# MMCSD2_CTL_CFG register map
Vendor: Texas Instruments
Registers are 16-bit, read-only, reset 0x0 unless marked. A register's access mark holds for its fields unless they carry their own. Offsets are as the file gives them; [hi:lo] are bit positions; {n}, {i} and the like mark numbered series.

## MMCSD2_CTL_CFG (part 2 of 3)
0x00 MMCSD12_SDMA_SYS_ADDR_LO rw — This register contains the Lower 16-bit of physical system memory address used for DMA transfers or the second argument for the Auto CMD23 in Host version 3.0 and as 32-bit Block Count in Version 4.10.
  [15:0] SDMA_ADDRESS — 32-bit Block Count (SDMA System Address) Low When the When the (1) SDMA System Address ( This register contains the system memory address for a SDMA transfer in 32-bit addressing mode. When the Host Controller (HC) stops a SDMA transfer, this register shall point to the system address of the next contiguous data position. It can be accessed only if no transaction is executing (after a transaction has stopped). Reading this register during SDMA transfers may return an invalid value. The Host Driver (HD) shall initialize this register before starting a SDMA transaction. After SDMA has stopped, the next system address of the next contiguous data position can be read from this register. The SDMA transfer waits at the every boundary specified by the (2) 32-bit Block Count ( Host Controller Version 4.10 re-defines this register as 32-bit Block Count. In version 4.00, this register may be used as 32-bit block count only for Auto CMD23 to set the argument of the CMD23 while executing Auto CMD23. The Host Controller would decrement the block count of this register every block transfer and data transfer stops when the count reaches zero.
0x02 MMCSD12_SDMA_SYS_ADDR_HI rw — This register contains the Upper 16-bit of physical system memory address used for DMA transfers or the second argument for the Auto CMD23 in Host version 3.0 and as 32-bit Block Count in Version 4.10.
  [15:0] SDMA_ADDRESS — 32-bit Block Count (SDMA System Address) High This register contains the Upper 16-bit of physical system memory address used for DMA transfers or the second argument for the Auto CMD23 in Host version 3.0 and as 32-bit Block Count in Version 4.10.
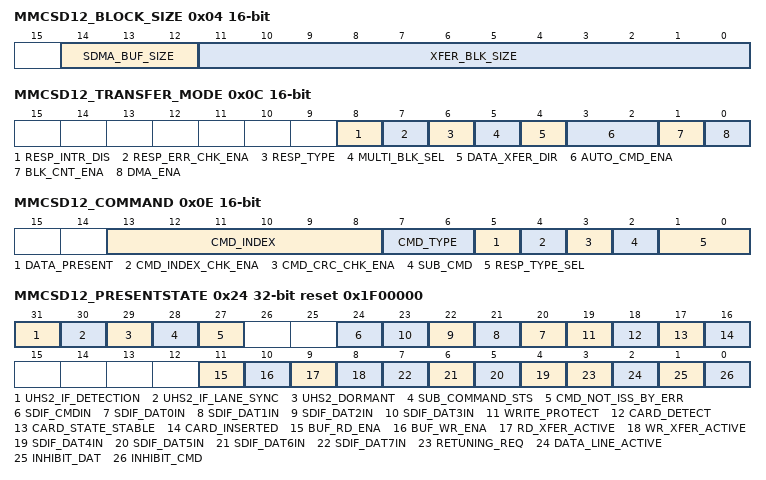
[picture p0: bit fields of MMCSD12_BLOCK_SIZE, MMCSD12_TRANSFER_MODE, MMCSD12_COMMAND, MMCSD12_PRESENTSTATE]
0x04 MMCSD12_BLOCK_SIZE access per field — This register is used to configure the number of bytes in a data block.
  [14:12] SDMA_BUF_SIZE rw — Host SDMA Buffer Size To perform long DMA transfer, System Address register ( These bits shall support when the 0h: 4KB (Detects A11 Carry out) 1h: 8KB (Detects A12 Carry out) 2h: 16KB (Detects A13 Carry out) 3h: 32KB (Detects A14 Carry out) 4h: 64KB (Detects A15 Carry out) 5h: 128KB (Detects A16 Carry out) 6h: 256KB (Detects A17 Carry out) 7h: 512KB (Detects A18 Carry out)
  [11:0] XFER_BLK_SIZE rw — Transfer Block Size This field specifies the block size for block data transfers for CMD17, CMD18, CMD24, CMD25 and CMD53. It can be accessed only if no transaction is executing (after a transaction has stopped). Read operations during transfer return an invalid value and write operations shall be ignored. 0000h: No Data Transfer 0001h: 1 Byte 0002h: 2 Bytes 0003h: 3 Bytes 0004h: 4 Bytes .... 01FFh: 511 Bytes 0200h: 512 Bytes .... 0800h: 2048 Bytes
0x06 MMCSD12_BLOCK_COUNT rw — This register is used to configure the number of data blocks.
  [15:0] XFER_BLK_CNT — 16-bit Block Count Host Controller Version 4.10 extends block count to 32-bit. Selection of either 16-bit Block Count register or 32-bit Block Count register is defined as follows: (1) If the (2) If the Use of 16-bit/32-bit Block Count register is enabled when the The Host Driver shall set this register to a value between 1h and the maximum block count. The Host Controller decrements the block count after each block transfer and stops when the count reaches zero. Setting the block count to 0h results in no data blocks is transferred. This register should be accessed only when no transaction is executing (after transactions are stopped). During data transfer, read operations on this register may return an invalid value and write operations are ignored. 0000h: Stop Count 0001h: 1 Block 0002h: 2 Blocks .... FFFFh: 65535 Blocks
0x08 MMCSD12_ARGUMENT1_LO rw — This register contains Lower bits of SD Command Argument.
  [15:0] CMD_ARG1 — Command Argument 1 Low The SD Command Argument is specified as bit 23-8 of Command-Format.
0x0A MMCSD12_ARGUMENT1_HI rw — This register contains higher bits of SD Command Argument.
  [15:0] CMD_ARG1 — Command Argument 1 High The SD Command Argument is specified as bit 39-24 of Command-Format.
0x0C MMCSD12_TRANSFER_MODE access per field
  [8] RESP_INTR_DIS rw — Response Interrupt Disable Host Controller Version 4.00 supports response error check function to avoid overhead of response error check by Host Driver. Only R1 or R5 can be checked. If Host Driver checks response error, sets this bit to 0h and waits Command Complete Interrupt ( If Host Controller checks response error, sets this bit to 1h and sets the 0h: Response Interrupt is enabled 1h: Response Interrupt is disabled
  [7] RESP_ERR_CHK_ENA rw — Response Error Check Enable Host Controller Version 4.00 supports response error check function to avoid overhead of response error check by Host Driver. Only R1 or R5 can be checked. If Host Driver checks response error, this bit is set to 0h and the If Host Controller checks response error, sets this bit to 1h and sets the Response Interrupt Disable bit to 1h ( The 0h: Response Error Check is disabled 1h: Response Error Check is enabled
  [6] RESP_TYPE rw — Response Type R1/R5 When response error check is enabled ( Error Statuses Checked in R1: Response Flags Checked in R5: 0h: R1 (Memory) 1h: R5 (SDIO)
  [5] MULTI_BLK_SEL rw — Multi/Single Block Select This bit enables multiple block data transfers. 0h: Single Block 1h: Multiple Block
  [4] DATA_XFER_DIR rw — Data Transfer Direction Select This bit defines the direction of data transfers. 0h: Write (Host to Card) 1h: Read (Card to Host)
  [3:2] AUTO_CMD_ENA rw — Auto CMD Enable This field determines use of auto command functions. There are three methods to stop Multiple-block read and write operation by CMD23 or CMD12. In the other operations (for example single read/write operation), this field is set to 0h. (1) Auto CMD12 Enable: Multiple-block read and write commands for memory require CMD12 to stop the operation. When this field is set to 1h, the Host Controller issues CMD12 automatically when last block transfer is completed. Auto CMD12 error is indicated to the When When (2) Auto CMD23 Enable: When this bit field is set to 2h, the Host Controller issues a CMD23 automatically before issuing a command specified in the The following conditions are required to use the Auto CMD23: Auto CMD23 Supported (Host Controller Version is 3.00 or later). A memory card that supports CMD23 (SCR[33] = 1h). If DMA is used, it shall be ADMA. Only when CMD18 or CMD25 is issued. Auto CMD23 can be used with or without ADMA. By writing the 32-bit block count value for CMD23 is set to 32-bit Block Count ( (3) Auto CMD Auto Select (Version 4.10): As CMD23 is optional for SD memory card except UHS 104 card, if card supports CMD23, Auto CMD 23 should be used instead of Auto CMD12. Host Controller Version 4.10 defines this 'Auto CMD Auto Select' mode. Selection of Auto CMD depends on setting of the 0h: Auto Command Disabled 1h: Auto CMD12 Enable 2h: Auto CMD23 Enable 3h: Reserved
  [1] BLK_CNT_ENA rw — Block Count Enable This bit is used to enable the 0h: Disable 1h: Enable
  [0] DMA_ENA rw — DMA Enable DMA can be enabled only if the 0h: Disable 1h: Enable
0x0E MMCSD12_COMMAND access per field — This register is used to program the Command for host controller.
  [13:8] CMD_INDEX rw — Command Index This bit shall be set to the command number (CMD0-63, ACMD0-63).
  [7:6] CMD_TYPE rw — Command Type There are three types of special commands. Suspend, Resume and Abort. These bits shall be set to 0h for all other commands. Suspend Command: Resume Command: Abort Command: 0h: Normal 1h: Suspend 2h: Resume 3h: Abort
  [5] DATA_PRESENT rw — Data Present Select This bit is set to 1h to indicate that data is present and shall be transferred using the DAT line. If is set to 0h for the following: 0h: No Data Present 1h: Data Present
  [4] CMD_INDEX_CHK_ENA rw — Command Index Check Enable If this bit is set to 1h, the HC shall check the index field in the response to see if it has the same value as the command index. If it is not, it is reported as a Command Index Error. If this bit is set to 0h, the Index field is not checked. 0h: Disable 1h: Enable
  [3] CMD_CRC_CHK_ENA rw — Command CRC Check Enable If this bit is set to 1h, the HC shall check the CRC field in the response. If an error is detected, it is reported as a Command CRC Error. If this bit is set to 0h, the CRC field is not checked. 0h: Disable 1h: Enable
  [2] SUB_CMD rw — Sub Command Flag This bit is added from Version 4.10 to distinguish a main command or sub command. When issuing a main command, this bit is set to 0h and when issuing a sub command, this bit is set to 1h. Setting of this bit is checked by the Host Driver manages whether main or sub command. Host Controller does not refer to this bit to issue a command. 0h: Sub Command 1h: Main Command
  [1:0] RESP_TYPE_SEL rw — Response Type Select 0h: No Response 1h: Response length 136 2h: Response length 48 3h: Response length 48 check Busy after response
{0x10+4i} MMCSD12_RESPONSE_{i} (i=0..6) — This registers is used to store responses from SD Cards.
  [15:0] CMD_RESP — Command Response R[] refers to a bit range within the response data as transmitted on the SD Bus, REP[] refers to a bit range within the Response register.
0x20 MMCSD12_DATA_PORT 32-bit rw — This register is used to access internal buffer.
  [31:0] BUF_RD_DATA — Buffer Data The Host Controller Buffer can be accessed through this 32-bit Data Port Register.
0x24 MMCSD12_PRESENTSTATE 32-bit reset 0x1F00000 — The Host Driver can get status of the Host Controller from this 32-bit read-only register.
  [31] UHS2_IF_DETECTION — UHS-II IF Detection (UHS-II Only) This status indicates whether a card supports UHS-II IF. This status is enabled by setting UHS-II Interface Enable to 1h in the Host Control 2 register ( After UHS-II IF is detected, this bit is cleared by when EIDL is detected on D0 lane, UHS-II Interface Enable is set to 0h ( 1h: UHS-II IF is detected 0h: UHS-II IF is not detected
  [30] UHS2_IF_LANE_SYNC — Lane Synchronization (UHS-II Only) This status indicates whether lane is synchronized in UHS-II mode. This status is enabled by setting UHS-II Interface Enable to 1h in the Host Control 2 register ( In case of Version 4.00, this bit indicates completion of Device PHY Initialization by detecting LIDL LSS on D1 lane. From Version 4.10, Host Controller may implement a specific PHY verification method and PHY Initialization Failure can be indicated by keeping this bit to 0h even LIDL LSS is detected on D1 lane. Host Driver detects PHY Initialization Failure by timeout. This bit is cleared by when D0 lane is set to EIDL, UHS-II Interface Enable is set to 0h ( 1h: UHS-II PHY is initialized 0h: UHS-II PHY is not initialized
  [29] UHS2_DORMANT — In Dormant State (UHS-II Only) This status indicates whether UHS-II lanes enter Dormant state. This function is enabled by setting UHS-II Interface Enable to 1h in the Host Control 2 register ( RCLK may be stopped in dormant state, by setting SD Clock Enable to 0h in the Clock Control register ( In case of the card enters Hibernate Mode (RCLK is stopped), Host Driver may turn off VDD1 by clearing SD Bus Power for VDD1 bit in the 1h: In DORMANT state 0h: Not in DORMANT state
  [28] SUB_COMMAND_STS — Sub Command Status The 1h: Sub Command Status 0h: Main Command Status
  [27] CMD_NOT_ISS_BY_ERR — Command Not Issued by Error Setting of this status indicates that a command cannot be issued due to an error except Auto CMD12 error (equivalent error status by Auto CMD12 error is defined as Command Not Issued By Auto CMD12 Error in the 1h: Command cannot be issued 0h: No error for issuing a command
  [24] SDIF_CMDIN — CMD Line Signal Level (SD Mode Only) This status is used to check CMD line level to recover from errors, and for debugging.
  [n+20] SDIF_DAT{n}IN (n=0..3) — DAT[{n}] Line Signal Level (SD Mode Only) This status is used to check DAT line level to recover from errors, and for debugging. This is especially useful in detecting the busy signal level from DAT[{n}]. D{n+20} - DAT[{n}]
  [19] WRITE_PROTECT — Write Protect Switch Pin Level The Write Protect Switch is supported for memory and combo cards.This bit reflects the SDWP# pin. 0h: Write protected (SDWP# = 1) 1h: Write enabled (SDWP# = 0)
  [18] CARD_DETECT — Card Detect Pin Level This bit reflects the inverse value of the SDCD# pin. 0h: No Card present (SDCD# = 1) 1h: Card present (SDCD# = 0)
  [17] CARD_STATE_STABLE — Card State Stable This bit is used for testing. If it is 0h, the Card Detect Pin Level is not stable. If this bit is set to 1h, it means the Card Detect Pin Level is stable. The 0h: Reset of Debouncing 1h: No Card or Inserted
  [16] CARD_INSERTED — Card Inserted This bit indicates whether a card has been inserted. Changing from 0h to 1h generates a Card Insertion interrupt in the If a Card is removed while its power is on and its clock is oscillating, the HC shall clear the 0h: Reset or Debouncing or No Card 1h: Card Inserted
  [11] BUF_RD_ENA — Buffer Read Enable This status is used for non-DMA read transfers. This read only flag indicates that valid data exists in the host side buffer status. If this bit is 1h, readable data exists in the buffer. A change of this bit from 1h to 0h occurs when all the block data is read from the buffer. A change of this bit from 0h to 1h occurs when all the block data is ready in the buffer and generates the Buffer Read Ready Interrupt. 0h: Read Disable 1h: Read Enable
  [10] BUF_WR_ENA — Buffer Write Enable This status is used for non-DMA write transfers. This read only flag indicates if space is available for write data. If this bit is 1h, data can be written to the buffer. A change of this bit from 1h to 0h occurs when all the block data is written to the buffer. A change of this bit from 0h to 1h occurs when top of block data can be written to the buffer and generates the Buffer Write Ready Interrupt. 0h: Write Disable 1h: Write Enable
  [9] RD_XFER_ACTIVE — Read Transfer Active (SD Mode Only) This status is used for detecting completion of a read transfer. This bit is set to 1h for either of the following conditions: This bit is cleared to 0h for either of the following conditions: 1h: Transferring data 0h: No valid data
  [8] WR_XFER_ACTIVE — Write Transfer Active (SD Mode Only) This status indicates a write transfer is active. If this bit is 0h, it means no valid write data exists in the HC. This bit is set in either of the following cases: This bit is cleared in either of the following cases: 1h: Transferring data 0h: No valid data
  [n] SDIF_DAT{n}IN (n=4..7) — DAT[{n}] Line Signal Level (Embedded Only) This status is used to check DAT line level to recover from errors, and for debugging. D{n:02} - DAT[{n}]
  [3] RETUNING_REQ — Re-Tuning Request (UHS-I Only) Host Controller may request Host Driver to execute re-tuning sequence by setting this bit when the data window is shifted by temperature drift and a tuned sampling point does not have a good margin to receive correct data. This bit is cleared when a command is issued with setting the Changing of this bit from 0h to 1h generates Re-Tuning Event. This bit isn't set to 1h if the 1h: Sampling clock needs re-tuning 0h: Fixed or well tuned sampling clock
  [2] DATA_LINE_ACTIVE — DAT Line Active (SD Mode Only) This bit indicates whether one of the DAT line on SD bus is in use. 1h: DAT line active 0h: DAT line inactive
  [1] INHIBIT_DAT — Command Inhibit (DAT) (SD Mode Only) This status bit is generated if either the DAT Line Active or the Read transfer Active is set to 1h. If this bit is 0h, it indicates the HC can issue the next SD command. Commands with busy signal belong to Command Inhibit (DAT) (for example R1b, R5b type). Changing from 1h to 0h generates a Transfer Complete interrupt in the 1h: Cannot issue command which uses the DAT line 0h: Can issue command which uses the DAT line
  [0] INHIBIT_CMD — Command Inhibit (CMD) 1h: Host Controller is not ready to issue a command 0h: Host Controller is ready to issue a command Version 4.10 adds a new control to prevent error statuses from overwriting by receipt of a next command. This status keeps indicating 1h while any of response error statuses is set to 1h, Command Not Issued by Error in this register is set to 1h or the
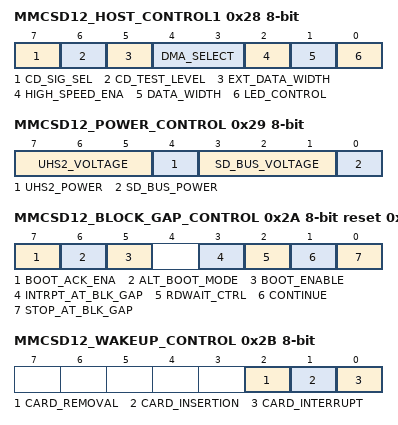
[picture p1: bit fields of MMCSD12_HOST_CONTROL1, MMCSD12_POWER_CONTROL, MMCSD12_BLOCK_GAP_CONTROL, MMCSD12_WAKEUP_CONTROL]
0x28 MMCSD12_HOST_CONTROL1 8-bit rw — This register is used to program DMA modes, LED control, data transfer width, High Speed enable, card detect test level and signal selection.
  [7] CD_SIG_SEL — Card Detect Signal Detection This bit selects source for card detection. 1h: The card detect test level is selected 0h: SDCD# is selected (for normal use)
  [6] CD_TEST_LEVEL — Card Detect Test Level This bit is enabled while the Card Detect Signal Selection is set to 1h and it indicates card inserted or not. Generates (card ins or card removal) interrupt when the normal interrupt status enable bit is set. 1h: Card Inserted 0h: No Card
  [5] EXT_DATA_WIDTH — Extended Data Transfer Width (Embedded and SD Mode Only) This bit controls 8-bit bus width mode for embedded device. Support of this function is indicated in 8-bit Support for Embedded Device in the This bit is not effective when multiple devices are installed on a bus slot (Slot Type is set to 2h in the 1h: 8-bit Bus Width 0h: Bus Width is Selected by Data Transfer Width
  [4:3] DMA_SELECT — DMA Select This field is used to select DMA type. The Host Driver shall check support of DMA modes by referring the (1) Up to Version 3.00: (2) Version 4.00 or later: Support of 64-bit DMA and 128-bit Descriptor is indicated by the
  [2] HIGH_SPEED_ENA — High Speed Enable (SD Mode Only) This bit is optional. Before setting this bit, the HD shall check the If the 1h: High Speed Mode 0h: Normal Speed Mode
  [1] DATA_WIDTH — Data Transfer Width (SD Mode Only) This bit selects the data width of the HC. The HD shall select it to match the data width of the SD card. This bit is not effective in UHS-II mode. 1h: 4 bit mode 0h: 1 bit mode
  [0] LED_CONTROL — LED Control This bit is used to caution the user not to remove the card while the SD card is being accessed. If the software is going to issue multiple SD commands, this bit can be set during all transactions. It is not necessary to change for each transaction. 1h: LED on 0h: LED off
0x29 MMCSD12_POWER_CONTROL 8-bit rw — This register is used to program the SD Bus power and voltage level.
  [7:5] UHS2_VOLTAGE — SD Bus Voltage Select for VDD2 (UHS-II Only) This field determines supply voltage range to VDD2. This field can be set to 5h if the 111b: Not used 110b: Not used 101b: 1.8 V 100b: Reserved for 1.2 V 011b – 001b: Reserved 000b: VDD2 Not Supported
  [4] UHS2_POWER — SD Bus Power for VDD2 (UHS-II Only) Setting this bit enables providing VDD2. 1h: Power on 0h: Power off
  [3:1] SD_BUS_VOLTAGE — SD Bus Voltage Select for VDD1 By setting these bits, the HD selects the voltage level for the SD card. Before setting this register, the HD shall check the voltage support bits in the 111b: 3.3 V (Flattop.) 110b: 3.0 V (Typ.) 101b: 1.8 V (Typ.) for Embedded 100b – 000b: Reserved
  [0] SD_BUS_POWER — SD Bus Power for VDD1 Before setting this bit, the SD host driver shall set SD Bus Voltage Select ( If this bit is cleared, the Host Controller should immediately stop driving CMD and DAT[3:0] (tri-state), and drive SDCLK to low level. If card is connected to Host Controller, Host Controller shall set these lines to low before stopping to supply VDD1. In UHS-II mode, before clearing this bit, Host Driver shall clear the 1h: Power on 0h: Power off
0x2A MMCSD12_BLOCK_GAP_CONTROL 8-bit access per field reset 0x80 — This register is used to program the block gap request, read wait control and interrupt at block gap.
  [7] BOOT_ACK_ENA rw — Boot Acknowledge Check To check for the boot acknowledge in boot operation. 1h: Wait for boot ack from eMMC card 0h: Will not wait for boot ack from eMMC card
  [6] ALT_BOOT_MODE rw — Alternative Boot Mode To start boot code access in alternative mode. 1h: To start alternate boot mode access 0h: To stop alternate boot mode access
  [5] BOOT_ENABLE rw — Boot Enable To start boot code access. 1h: To start boot code access 0h: To stop boot code access
  [3] INTRPT_AT_BLK_GAP rw — Interrupt At Block Gap (SD Mode Only) This bit is valid only in 4-bit mode of the SDIO card and selects a sample point in the interrupt cycle. Setting to 1h enables interrupt detection at the block gap for a multiple block transfer. If the SD card cannot signal an interrupt during a multiple block transfer, this bit should be set to 0h. When the HD detects an SD card insertion, it shall set this bit according to the CCCR of the SDIO card.
  [2] RDWAIT_CTRL rw — Read Wait Control (SD Mode Only) The read wait function is optional for SDIO cards. If the card supports read wait, set this bit to enable use of the read wait protocol to stop read data using DAT[2] line. Otherwise the HC has to stop the SD clock to hold read data, which restricts commands generation. When the HD detects an SD card insertion, it shall set this bit according to the CCCR of the SDIO card. If the card does not support read wait, this bit shall never be set to 1h otherwise DAT line conflict may occur. If this bit is set to 0h, Suspend/Resume cannot be supported. In UHS-II mode, Read Wait is disabled and DAT[2] line is used for Interrupt Signal from UHS-II Card. 1h: Enable Read Wait Control 0h: Disable Read Wait Control
  [1] CONTINUE rw — Continue Request This bit is used to restart a transaction which was stopped using the Stop At Block Gap Request. To cancel stop at the block gap, set Stop At block Gap Request to 0h ( The Host Controller automatically clears this bit when the transaction re-starts. If In SD mode, this bit is cleared in either of the following cases: Therefore it is not necessary for Host driver to set this bit to 0h. If 1h: Restart 0h: Ignored
  [0] STOP_AT_BLK_GAP rw — Stop At Block Gap Request This bit is used to stop executing a transaction at the next block gap for non-DMA, SDMA and ADMA transfers. Until the transfer complete is set to 1h, indicating a transfer completion the HD shall leave this bit set to 1h. Clearing both the In case of UHS-II, a transaction can be stopped at the boundary of DATA Burst (Flow Control basis). Host Controller waits for sending Flow Control MSG until the 1h: Stop 0h: Transfer
0x2B MMCSD12_WAKEUP_CONTROL 8-bit access per field — This register is used to program the wakeup functionality. The register is mandatory for the HC, but wakeup functionality depends on the HC system hardware and software. The HD shall maintain voltage on the SD Bus, by setting the [0] SD_BUS_POWER bit to 1h, when wakeup event via card interrupt is desired.
  [2] CARD_REMOVAL rw — Wakeup Event Enable On SD Card Removal This bit enables wakeup event via Card removal assertion in the FN_WUS (Wake up Support) in CIS does not affect this bit. 1h: Enable 0h: Disable
  [1] CARD_INSERTION rw — Wakeup Event Enable On SD Card Insertion This bit enables wakeup event via Card Insertion assertion in the FN_WUS (Wake up Support) in CIS does not affect this bit. 1h: Enable 0h: Disable
  [0] CARD_INTERRUPT rw — Wakeup Event Enable On Card Interrupt This bit enables wakeup event via Card Interrupt assertion in the This bit can be set to 1h if FN_WUS (Wake Up Support) in CIS is set to 1h. 1h: Enable 0h: Disable
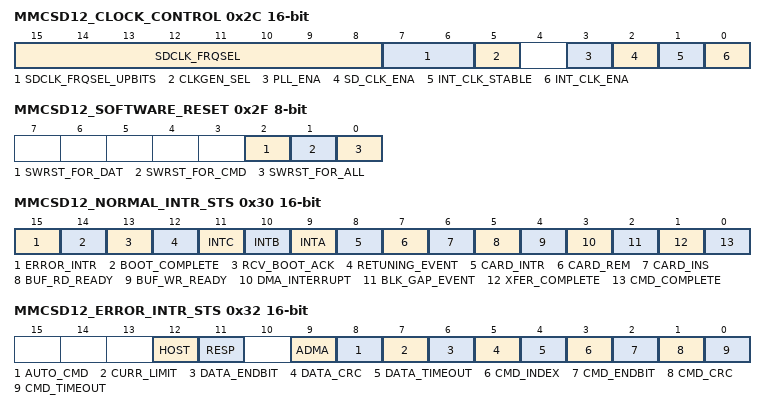
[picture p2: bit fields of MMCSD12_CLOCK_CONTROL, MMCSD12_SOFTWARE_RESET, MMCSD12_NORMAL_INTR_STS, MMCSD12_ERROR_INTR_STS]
0x2C MMCSD12_CLOCK_CONTROL access per field — This register is used to program the Clock frequency select, Clock generator select, Clock enable, Internal clock state fields. At the initialization of the HC, the HD shall set the SDCLK Frequency Select ([15-8] SDCLK_FRQSEL) according to the register. This register controls SDCLK in SD Mode and RCLK in UHS-II mode.
  [15:8] SDCLK_FRQSEL rw — SDCLK/RCLK Frequency Select This register is used to select the frequency of the SDCLK pin. The frequency is not programmed directly; rather this register holds the divisor of the Base Clock Frequency For SD clock in the Capabilities register ( Only the following settings are allowed. (1) 8-bit Divided Clock Mode: Setting 00h specifies the highest frequency of the SD Clock. When setting multiple bits, the most significant bit is used as the divisor. But multiple bits should not be set. The three default divider values can be calculated by the frequency that is defined by the 400 KHz divider value 25 MHz divider value 50 MHz divider value According to the Physical Layer Specification, the maximum SD Clock frequency is 25 MHz in normal speed mode and 50 MHz in high speed mode, and shall never exceed this limit. The frequency of SDCLK is set by the following formula: Clock Frequency = (Base Clock) / divisor Thus, choose the smallest possible divisor which results in a clock frequency that is less than or equal to the target frequency. For example, if the (2) 10-bit Divided Clock Mode: (3) Programmable Clock Mode: This field depends on setting of the If If
  [7:6] SDCLK_FRQSEL_UPBITS rw — Upper Bits of SDCLK/RCLK Frequency Select This bit field is assigned to the
  [5] CLKGEN_SEL rw — Clock Generator Select This bit is used to select the clock generator mode in SDCLK/RCLK Frequency Select ( If the Programmable Clock Mode is supported (non-zero value is set to the This bit depends on the setting of the If If 1h: Programmable Clock Mode 0h: Divided Clock Mode
  [3] PLL_ENA rw — PLL Enable This bit is added from Version 4.10 for Host Controller using PLL. This feature allows Host Controller to initialize clock generator in two steps: by Internal Clock Enable ( (1) When (2) When 1h: PLL is enabled 0h: PLL is in low power mode
  [2] SD_CLK_ENA rw — SD Clock Enable The HC shall stop SDCLK when writing this bit to 0h. The 1h: Enable providing SDCLK or RCLK 0h: Disable providing SDCLK or RCLK
  [1] INT_CLK_STABLE ro — Internal Clock Stable This bit is set to 1h when SD clock is stable after writing 1h to (1) Internal Clock Stable (when This bit is set to 1h when internal clock is stable after writing 1h to (2) PLL Clock Stable (when Host Controller which supports PLL Enable sets this status to 0h once when PLL Enable is changed 0h to 1h and then this status is set to 1h when PLL is locked (PLL uses an internal clock in stable as a reference clock which is enabled by the 1h: Ready 0h: Not Ready
  [0] INT_CLK_ENA rw — Internal Clock Enable This bit is set to 0h when the HD is not using the HC or the HC awaits a wakeup event. The HC should stop its internal clock to go very low power state. Still, registers shall be able to be read and written. Clock starts to oscillate when this bit is set to 1h. When clock oscillation is stable, the HC shall set the 1h: Oscillate 0h: Stop
0x2E MMCSD12_TIMEOUT_CONTROL 8-bit access per field — The register sets the data timeout counter value. At the initialization of the HC, the HD shall set the Data Timeout Counter Value according to the register.
  [3:0] COUNTER_VALUE rw — Data Timeout Counter Value This value determines the interval by which DAT line time-outs are detected. Refer to the 1111: Reserved 1110: TMCLK × 2 -------------------- -------------------- 0001: TMCLK × 2 0000: TMCLK × 2
0x2F MMCSD12_SOFTWARE_RESET 8-bit access per field — This register is used to program the software reset for data, command and for all. A reset pulse is generated when writing 1h to each bit of this register. After completing the reset, the HC shall clear each bit. Because it takes some time to complete software reset, the SD Host Driver shall confirm that these bits are 0h.
  [2] SWRST_FOR_DAT rw — Software Reset for DAT Line (SD Mode Only) Only part of data circuit is reset. The following registers and bits are cleared by this bit: 1h: Reset 0h: Work
  [1] SWRST_FOR_CMD rw — Software Reset for CMD Line (SD Mode Only) Only part of command circuit is reset to be able to issue a command. From Version 4.10, this bit is also used to initialize UHS-II command circuit. This reset is effective only command issuing circuit (including response error statuses related to Command Inhibit (CMD) control - The following registers and bits are cleared by this bit: Response error statuses related to Command Inhibit (CMD) - 1h: Reset 0h: Work
  [0] SWRST_FOR_ALL rw — Software Reset for All This reset affects the entire HC except for the card detection circuit. Register bits of type ROC, RW, RW1C, RWAC are cleared to 0h. During its initialization, the HD shall set this bit to 1h to reset the HC. The HC shall reset this bit to 0h when Capabilities registers are valid and the HD can read them. Additional use of 'Software Reset For All' may not affect the value of the Capabilities registers. If this bit is set to 1h, the SD card shall reset itself and must be re-initialized by the HD. 1h: Reset 0h: Work
0x30 MMCSD12_NORMAL_INTR_STS access not given — This register gives the status of all the interrupts. The Normal Interrupt Signal Enable (see register) affects read of this register, but Normal Interrupt Signal does not affect these reads. An Interrupt is generated when the Normal Interrupt Signal Enable is enabled and at least one of the status bits is set to 1h. For all bits except Card Interrupt ([8] CARD_INTR) and Error Interrupt ([15] ERROR_INTR), writing 1h to a bit clears it. The [8] CARD_INTR bit is cleared when the card stops asserting the interrupt: that is when the Card Driver services the Interrupt condition.
  [15] ERROR_INTR ro — Error Interrupt If any of the bits in the In UHS-II mode is enabled, if any of the bits in the 0h: No Error 1h: Error
  [14] BOOT_COMPLETE — Boot Terminate Interrupt This status is set if the boot operation gets terminated. 0h: Boot operation is not terminated 1h: Boot operation is terminated (access RW1C)
  [13] RCV_BOOT_ACK — Boot Acknowledge Receive This status is set if the boot acknowledge is received from device. 0h: Boot acknowledge is not received 1h: Boot acknowledge is received (access RW1C)
  [12] RETUNING_EVENT ro — Re-Tuning Event (UHS-I Only) This status is set if the Host Controller requests Host Driver to perform re-tuning for next data transfer. Current data transfer (not large block count) can be completed without re-tuning. In UHS-II mode, this bit is not effective. 1h: Re-Tuning should be performed 0h: Re-Tuning is not required
  [11] INTC ro — int_c (Embedded) This status is set if INT_C is enabled and INT_C# pin is in low level. Writing this bit to 1h does not clear this bit. It is cleared by resetting the INT_C interrupt factor.
  [10] INTB ro — int_b (Embedded) This status is set if INT_B is enabled and INT_B# pin is in low level. Writing this bit to 1h does not clear this bit. It is cleared by resetting the INT_B interrupt factor.
  [9] INTA ro — int_a (Embedded) This status is set if INT_A is enabled and INT_A# pin is in low level. Writing this bit to 1h does not clear this bit. It is cleared by resetting the INT_A interrupt factor.
  [8] CARD_INTR ro — Card Interrupt When this status has been set and the Host Driver needs to start this interrupt service, the Writing this bit to 1h does not clear this bit. It is cleared by resetting the SD card interrupt factor. (1) DAT[1] Interrupt Input in SD Mode In 1-bit mode, the Host Controller shall detect the Card Interrupt without SD Clock to support wakeup. In 4-bit mode, the card interrupt signal is sampled during the interrupt cycle, so there are some sample delays between the interrupt signal from the SD card and the interrupt to the Host System. Interrupt detected by DAT[1] is supported when there is a card per slot. In case of UHS-I mode, switching time of Interrupt Period is relaxed for 2 clock cycles. Then Host Controller needs to delay start of interrupt sampling at least 2 clocks and should sample interrupt while Interrupt Period is stable. (2) DAT[2] Interrupt Input in UHS-II Mode When the (3) INT MSG in UHS-II Mode INT MSG is enabled by setting the 1h: Generate Card Interrupt 0h: No Card Interrupt
  [7] CARD_REM — Card Removal This status is set if the 0h: Card State Stable or Debouncing 1h: Card Removed (access RW1C)
  [6] CARD_INS — Card Insertion This status is set if the 0h: Card State Stable or Debouncing 1h: Card Inserted (access RW1C)
  [5] BUF_RD_READY — Buffer Read Ready This status is set if the The In UHS-II mode, this bit is set at FC (Flow Control) unit basis. 0h: Not Ready to read Buffer 1h: Ready to read Buffer (access RW1C)
  [4] BUF_WR_READY — Buffer Write Ready This status is set if the In UHS-II mode, this bit is set at FC (Flow Control) unit basis. 0h: Not Ready to Write Buffer 1h: Ready to Write Buffer (access RW1C)
  [3] DMA_INTERRUPT — DMA Interrupt This status is set if the HC detects the Host DMA Buffer Boundary in the 0h: No DMA Interrupt 1h: DMA Interrupt is Generated (access RW1C)
  [2] BLK_GAP_EVENT — Block Gap Event If the Read Transaction: This bit is set at the falling edge of the DAT Line Active Status (see Write Transaction: This bit is set at the falling edge of Write Transfer Active Status (see 0h: No Block Gap Event 1h: Transaction stopped at Block Gap (access RW1C)
  [1] XFER_COMPLETE — Transfer Complete This bit is set when a read/write transaction is completed. Read Transaction: This bit is set at the falling edge of Read Transfer Active Status ( There are two cases in which the Interrupt is generated. The first is when a data transfer is completed as specified by data length (after the last data has been read to the Host System). The second is when data has stopped at the block gap and completed the data transfer by setting the Write Transaction: This bit is set at the falling edge of the DAT Line Active Status (see Command with Busy: This bit is set when busy is de-asserted. Refer to DAT Line Active and Command Inhibit (DAT) in the While performing tuning procedure (the 0h: No Data Transfer Complete 1h: Data Transfer Complete This interrupt is generated in following two cases: (a) EBSY Completion (for EBSY supported commands) When the (b) Stop and Continue during DCMD Data Transfer When the Following is for both SD mode and UHS-II mode. The table below shows that the 1h: Command execution is completed 0h: Not complete (access RW1C)
  [0] CMD_COMPLETE — Command Complete This bit is set when we get the end bit of the command response (Except Auto CMD12 and Auto CMD23). Version 4.00 defines response check function for R1 and R5. If the If the If the 0h: No Command Complete 1h: Command Complete (access RW1C)
0x32 MMCSD12_ERROR_INTR_STS access not given — This register gives the status of the error interrupts. Status defined in this register can be enabled by the register, but not by the register. The Interrupt is generated when the register is enabled and at least one of the statuses is set to 1h. Writing to 1h clears the bit and writing to 0h keeps the bit unchanged. More than one status can be cleared at the one register write.
  [12] HOST — Target Response Error Occurs when detecting ERROR in m_hresp (DMA transaction) 0h: No error 1h: Error (access RW1C)
  [11] RESP — Response Error (SD Mode Only) Host Controller Version 4.00 supports response error check function to avoid overhead of response error check by Host Driver during DMA execution. If the 0h: No error 1h: Error (access RW1C)
  [9] ADMA — ADMA Error This bit is set when the Host Controller detects errors during ADMA based data transfer. The state of the ADMA at an error occurrence is saved in the 0h: No error 1h: Error (access RW1C)
  [8] AUTO_CMD — Auto CMD Error (SD Mode Only) Auto CMD12 and Auto CMD23 use this error status. This bit is set when detecting that any of the bits D00 to D05 in the 0h: No error 1h: Error (access RW1C)
  [7] CURR_LIMIT — Current Limit Error By setting the 0h: No error 1h: Power Fail (access RW1C)
  [6] DATA_ENDBIT — Data End Bit Error (SD Mode Only) Occurs when detecting 0 at the end bit position of read data which uses the DAT line or the end bit position of the CRC status. 0h: No error 1h: Error (access RW1C)
  [5] DATA_CRC — Data CRC Error (SD Mode Only) Occurs when detecting CRC error when transferring read data which uses the DAT line or when detecting the Write CRC Status having a value of other than 2h. 0h: No error 1h: Error (access RW1C)
  [4] DATA_TIMEOUT — Data Timeout Error (SD Mode Only) Occurs when detecting one of following timeout conditions: 0h: No error 1h: Timeout (access RW1C)
  [3] CMD_INDEX — Command Index Error (SD Mode Only) Occurs if a Command Index error occurs in the Command Response ( 0h: No error 1h: Error (access RW1C)
  [2] CMD_ENDBIT — Command End Bit Error (SD Mode Only) Occurs when detecting that the end bit of a command response is 0h. 0h: No error 1h: End Bit Error Generated (access RW1C)
  [1] CMD_CRC — Command CRC Error (SD Mode Only) Command CRC Error is generated in two cases. 1. If a response is returned and the 2. The HC detects a CMD line conflict by monitoring the CMD line when a command is issued. If the HC drives the CMD line to 1 level, but detects 0 level on the CMD line at the next SDCLK edge, then the HC shall abort the command (Stop driving CMD line) and set this bit to 1h. The 0h: No error 1h: CRC Error Generated (access RW1C)
  [0] CMD_TIMEOUT — Command Timeout Error (SD Mode Only) Occurs only if the no response is returned within 64 SDCLK cycles from the end bit of the command. If the HC detects a CMD line conflict, in which case the 0h: No error 1h: Timeout (access RW1C)
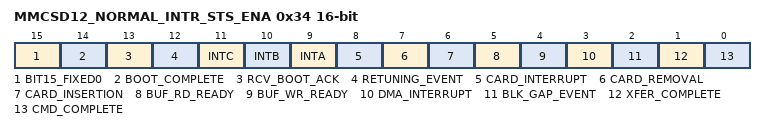
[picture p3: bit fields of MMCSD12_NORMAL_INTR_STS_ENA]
0x34 MMCSD12_NORMAL_INTR_STS_ENA access per field — This register is used to enable the register fields.
  [15] BIT15_FIXED0 ro — Fixed to 0 The HC shall control error Interrupts using the
  [14] BOOT_COMPLETE rw — Boot Terminate Interrupt Enable 0h: Masked 1h: Enabled
  [13] RCV_BOOT_ACK rw — Boot Acknowledge Enable 0h: Masked 1h: Enabled
  [12] RETUNING_EVENT rw — Re-Tuning Event Status Enable (UHS-I Only) 0h: Masked 1h: Enabled
  [11] INTC rw — INT_C Status Enable (Embedded) If this bit is set to 0h, the Host Controller shall clear the interrupt request to the System. The Host Driver may clear this bit before servicing the INT_C and may set this bit again after all interrupt requests to INT_C pin are cleared to prevent inadvertent interrupts.
  [10] INTB rw — INT_B Status Enable (Embedded) If this bit is set to 0h, the Host Controller shall clear the interrupt request to the System. The Host Driver may clear this bit before servicing the INT_B and may set this bit again after all interrupt requests to INT_B pin are cleared to prevent inadvertent interrupts.
  [9] INTA rw — INT_A Status Enable (Embedded) If this bit is set to 0h, the Host Controller shall clear the interrupt request to the System. The Host Driver may clear this bit before servicing the INT_A and may set this bit again after all interrupt requests to INT_A pin are cleared to prevent inadvertent interrupts.
  [8] CARD_INTERRUPT rw — Card Interrupt Status Enable If this bit is set to 0h, the HC shall clear Interrupt request to the System. The Card Interrupt detection is stopped when this bit is cleared and restarted when this bit is set to 1h. The HD may clear the By setting this bit to 0h, interrupt input should be masked by implementation so that the interrupt Input is not affected by external signal in any state (for example: floating). 0h: Masked 1h: Enabled
  [7] CARD_REMOVAL rw — Card Removal Status Enable 0h: Masked 1h: Enabled
  [6] CARD_INSERTION rw — Card Insertion Status Enable 0h: Masked 1h: Enabled
  [5] BUF_RD_READY rw — Buffer Read Ready Status Enable 0h: Masked 1h: Enabled
  [4] BUF_WR_READY rw — Buffer Write Ready Status Enable 0h: Masked 1h: Enabled
  [3] DMA_INTERRUPT rw — DMA Interrupt Status Enable 0h: Masked 1h: Enabled
  [2] BLK_GAP_EVENT rw — Block Gap Event Status Enable 0h: Masked 1h: Enabled
  [1] XFER_COMPLETE rw — Transfer Complete Status Enable 0h: Masked 1h: Enabled
  [0] CMD_COMPLETE rw — Command Complete Status Enable 0h: Masked 1h: Enabled
